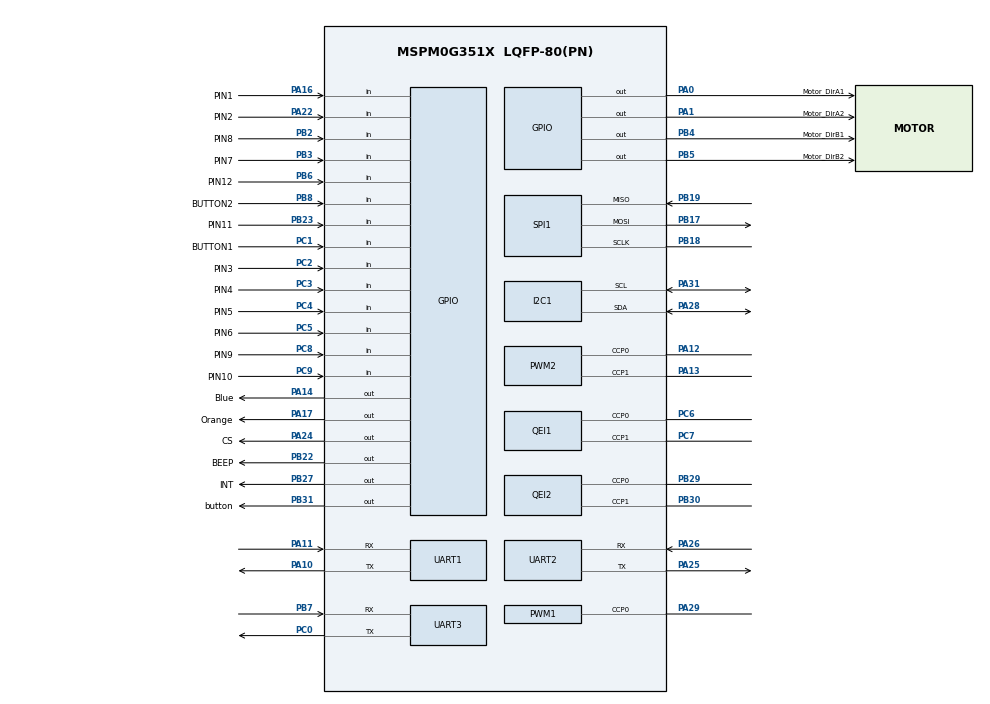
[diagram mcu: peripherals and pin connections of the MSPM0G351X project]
/**
 *
 * @cliArgs --device "MSPM0G351X" --part "Default" --package "LQFP-80(PN)" --product "mspm0_sdk@2.11.00.07"
 * @versions {"tool":"1.28.0+4712"}
 */

/**
 * Import the modules used in this configuration.
 */
const GPIO          = scripting.addModule("/ti/driverlib/GPIO", {}, false);
const GPIO1         = GPIO.addInstance();
const GPIO2         = GPIO.addInstance();
const GPIO3         = GPIO.addInstance();
const GPIO4         = GPIO.addInstance();
const GPIO5         = GPIO.addInstance();
const I2C           = scripting.addModule("/ti/driverlib/I2C", {}, false);
const I2C1          = I2C.addInstance();
const PWM           = scripting.addModule("/ti/driverlib/PWM", {}, false);
const PWM1          = PWM.addInstance();
const PWM2          = PWM.addInstance();
const QEI           = scripting.addModule("/ti/driverlib/QEI", {}, false);
const QEI1          = QEI.addInstance();
const QEI2          = QEI.addInstance();
const SPI           = scripting.addModule("/ti/driverlib/SPI", {}, false);
const SPI1          = SPI.addInstance();
const SYSCTL        = scripting.addModule("/ti/driverlib/SYSCTL");
const SYSTICK       = scripting.addModule("/ti/driverlib/SYSTICK");
const TIMER         = scripting.addModule("/ti/driverlib/TIMER", {}, false);
const TIMER1        = TIMER.addInstance();
const UART          = scripting.addModule("/ti/driverlib/UART", {}, false);
const UART1         = UART.addInstance();
const UART2         = UART.addInstance();
const UART3         = UART.addInstance();
const ProjectConfig = scripting.addModule("/ti/project_config/ProjectConfig");

/**
 * Write custom configuration values to the imported modules.
 */
const divider9       = system.clockTree["UDIV"];
divider9.divideValue = 2;

const mux4       = system.clockTree["EXHFMUX"];
mux4.inputSelect = "EXHFMUX_XTAL";

const mux8       = system.clockTree["HSCLKMUX"];
mux8.inputSelect = "HSCLKMUX_SYSPLL2X";

const mux10       = system.clockTree["MFPCLKMUX"];
mux10.inputSelect = "MFPCLKMUX_HFCLK";

const mux12       = system.clockTree["SYSPLLMUX"];
mux12.inputSelect = "zSYSPLLMUX_HFCLK";

const pinFunction4       = system.clockTree["HFXT"];
pinFunction4.enable      = true;
pinFunction4.inputFreq   = 40;
pinFunction4.HFXTStartup = 100;

GPIO1.$name                          = "LED_Board";
GPIO1.port                           = "PORTA";
GPIO1.associatedPins.create(2);
GPIO1.associatedPins[0].$name        = "Blue";
GPIO1.associatedPins[0].initialValue = "SET";
GPIO1.associatedPins[0].pin.$assign  = "PA14";
GPIO1.associatedPins[1].$name        = "Orange";
GPIO1.associatedPins[1].initialValue = "SET";
GPIO1.associatedPins[1].pin.$assign  = "PA17";

const Board = scripting.addModule("/ti/driverlib/Board", {}, false);

GPIO2.$name                         = "Button";
GPIO2.port                          = "PORTB";
GPIO2.associatedPins[0].$name       = "button";
GPIO2.associatedPins[0].pin.$assign = "PB31";

GPIO3.$name                          = "GraySensor";
GPIO3.associatedPins.create(12);
GPIO3.associatedPins[0].$name        = "PIN1";
GPIO3.associatedPins[0].direction    = "INPUT";
GPIO3.associatedPins[0].pin.$assign  = "PA16";
GPIO3.associatedPins[1].$name        = "PIN2";
GPIO3.associatedPins[1].direction    = "INPUT";
GPIO3.associatedPins[1].pin.$assign  = "PA22";
GPIO3.associatedPins[2].$name        = "PIN3";
GPIO3.associatedPins[2].direction    = "INPUT";
GPIO3.associatedPins[2].pin.$assign  = "PC2";
GPIO3.associatedPins[3].$name        = "PIN4";
GPIO3.associatedPins[3].direction    = "INPUT";
GPIO3.associatedPins[3].pin.$assign  = "PC3";
GPIO3.associatedPins[4].$name        = "PIN5";
GPIO3.associatedPins[4].direction    = "INPUT";
GPIO3.associatedPins[4].pin.$assign  = "PC4";
GPIO3.associatedPins[5].$name        = "PIN6";
GPIO3.associatedPins[5].direction    = "INPUT";
GPIO3.associatedPins[5].pin.$assign  = "PC5";
GPIO3.associatedPins[6].$name        = "PIN7";
GPIO3.associatedPins[6].direction    = "INPUT";
GPIO3.associatedPins[6].pin.$assign  = "PB3";
GPIO3.associatedPins[7].$name        = "PIN8";
GPIO3.associatedPins[7].direction    = "INPUT";
GPIO3.associatedPins[7].pin.$assign  = "PB2";
GPIO3.associatedPins[8].$name        = "PIN9";
GPIO3.associatedPins[8].direction    = "INPUT";
GPIO3.associatedPins[8].pin.$assign  = "PC8";
GPIO3.associatedPins[9].$name        = "PIN10";
GPIO3.associatedPins[9].direction    = "INPUT";
GPIO3.associatedPins[9].pin.$assign  = "PC9";
GPIO3.associatedPins[10].$name       = "PIN11";
GPIO3.associatedPins[10].direction   = "INPUT";
GPIO3.associatedPins[10].pin.$assign = "PB23";
GPIO3.associatedPins[11].$name       = "PIN12";
GPIO3.associatedPins[11].direction   = "INPUT";
GPIO3.associatedPins[11].pin.$assign = "PB6";

GPIO4.$name                          = "ICM";
GPIO4.associatedPins.create(2);
GPIO4.associatedPins[0].$name        = "CS";
GPIO4.associatedPins[0].pin.$assign  = "PA24";
GPIO4.associatedPins[1].$name        = "INT";
GPIO4.associatedPins[1].assignedPort = "PORTB";
GPIO4.associatedPins[1].pin.$assign  = "PB27";

GPIO5.$name                              = "MESS";
GPIO5.associatedPins.create(7);
GPIO5.associatedPins[0].$name            = "BUTTON1";
GPIO5.associatedPins[0].direction        = "INPUT";
GPIO5.associatedPins[0].internalResistor = "PULL_UP";
GPIO5.associatedPins[0].pin.$assign      = "PC1";
GPIO5.associatedPins[1].$name            = "BUTTON2";
GPIO5.associatedPins[1].direction        = "INPUT";
GPIO5.associatedPins[1].internalResistor = "PULL_UP";
GPIO5.associatedPins[1].inputFilter      = "3_CYCLES";
GPIO5.associatedPins[1].pin.$assign      = "PB8";
GPIO5.associatedPins[2].$name            = "BEEP";
GPIO5.associatedPins[2].pin.$assign      = "PB22";
GPIO5.associatedPins[3].$name            = "Motor_DirA1";
GPIO5.associatedPins[3].pin.$assign      = "PA0";
GPIO5.associatedPins[4].$name            = "Motor_DirA2";
GPIO5.associatedPins[4].pin.$assign      = "PA1";
GPIO5.associatedPins[5].$name            = "Motor_DirB1";
GPIO5.associatedPins[5].pin.$assign      = "PB4";
GPIO5.associatedPins[6].$name            = "Motor_DirB2";
GPIO5.associatedPins[6].pin.$assign      = "PB5";

I2C1.$name                     = "I2C_0";
I2C1.basicEnableController     = true;
I2C1.peripheral.sdaPin.$assign = "PA28";
I2C1.peripheral.sclPin.$assign = "PA31";
I2C1.sdaPinConfig.$name        = "ti_driverlib_gpio_GPIOPinGeneric10";
I2C1.sclPinConfig.$name        = "ti_driverlib_gpio_GPIOPinGeneric11";

PWM1.ccIndex                            = [0];
PWM1.$name                              = "LED_Color";
PWM1.timerCount                         = 100;
PWM1.interrupts                         = ["LOAD_EVENT"];
PWM1.timerStartTimer                    = true;
PWM1.PWM_CHANNEL_0.$name                = "ti_driverlib_pwm_PWMTimerCC0";
PWM1.PWM_CHANNEL_0.dutyCycle            = 50;
PWM1.ccp0PinConfig.direction            = scripting.forceWrite("OUTPUT");
PWM1.ccp0PinConfig.hideOutputInversion  = scripting.forceWrite(false);
PWM1.ccp0PinConfig.onlyInternalResistor = scripting.forceWrite(false);
PWM1.ccp0PinConfig.passedPeripheralType = scripting.forceWrite("Digital");
PWM1.ccp0PinConfig.$name                = "ti_driverlib_gpio_GPIOPinGeneric6";
PWM1.peripheral.$assign                 = "TIMG6";
PWM1.peripheral.ccp0Pin.$assign         = "PA29";

PWM2.$name                              = "PWM_Motor";
PWM2.timerCount                         = 1001;
PWM2.peripheral.ccp0Pin.$assign         = "PA12";
PWM2.peripheral.ccp1Pin.$assign         = "PA13";
PWM2.PWM_CHANNEL_0.$name                = "ti_driverlib_pwm_PWMTimerCC1";
PWM2.PWM_CHANNEL_1.$name                = "ti_driverlib_pwm_PWMTimerCC2";
PWM2.ccp0PinConfig.direction            = scripting.forceWrite("OUTPUT");
PWM2.ccp0PinConfig.hideOutputInversion  = scripting.forceWrite(false);
PWM2.ccp0PinConfig.onlyInternalResistor = scripting.forceWrite(false);
PWM2.ccp0PinConfig.passedPeripheralType = scripting.forceWrite("Digital");
PWM2.ccp0PinConfig.$name                = "ti_driverlib_gpio_GPIOPinGeneric14";
PWM2.ccp1PinConfig.direction            = scripting.forceWrite("OUTPUT");
PWM2.ccp1PinConfig.hideOutputInversion  = scripting.forceWrite(false);
PWM2.ccp1PinConfig.onlyInternalResistor = scripting.forceWrite(false);
PWM2.ccp1PinConfig.passedPeripheralType = scripting.forceWrite("Digital");
PWM2.ccp1PinConfig.$name                = "ti_driverlib_gpio_GPIOPinGeneric15";

QEI1.$name                              = "QEI_1";
QEI1.timerStartTimer                    = true;
QEI1.peripheral.ccp0Pin.$assign         = "PC6";
QEI1.peripheral.ccp1Pin.$assign         = "PC7";
QEI1.ccp0PinConfig.hideOutputInversion  = scripting.forceWrite(false);
QEI1.ccp0PinConfig.onlyInternalResistor = scripting.forceWrite(false);
QEI1.ccp0PinConfig.passedPeripheralType = scripting.forceWrite("Digital");
QEI1.ccp0PinConfig.$name                = "ti_driverlib_gpio_GPIOPinGeneric2";
QEI1.ccp1PinConfig.hideOutputInversion  = scripting.forceWrite(false);
QEI1.ccp1PinConfig.onlyInternalResistor = scripting.forceWrite(false);
QEI1.ccp1PinConfig.passedPeripheralType = scripting.forceWrite("Digital");
QEI1.ccp1PinConfig.$name                = "ti_driverlib_gpio_GPIOPinGeneric3";

QEI2.$name                              = "QEI_0";
QEI2.timerStartTimer                    = true;
QEI2.peripheral.ccp0Pin.$assign         = "PB29";
QEI2.peripheral.ccp1Pin.$assign         = "PB30";
QEI2.ccp0PinConfig.hideOutputInversion  = scripting.forceWrite(false);
QEI2.ccp0PinConfig.onlyInternalResistor = scripting.forceWrite(false);
QEI2.ccp0PinConfig.passedPeripheralType = scripting.forceWrite("Digital");
QEI2.ccp0PinConfig.$name                = "ti_driverlib_gpio_GPIOPinGeneric0";
QEI2.ccp1PinConfig.hideOutputInversion  = scripting.forceWrite(false);
QEI2.ccp1PinConfig.onlyInternalResistor = scripting.forceWrite(false);
QEI2.ccp1PinConfig.passedPeripheralType = scripting.forceWrite("Digital");
QEI2.ccp1PinConfig.$name                = "ti_driverlib_gpio_GPIOPinGeneric1";

SPI1.$name                      = "SPI_0";
SPI1.enableDMAEvent1            = false;
SPI1.enableDMAEvent2            = false;
SPI1.frameFormat                = "MOTO3";
SPI1.chipSelect                 = [];
SPI1.polarity                   = "1";
SPI1.phase                      = "1";
SPI1.targetBitRate              = 6000000;
SPI1.sclkPinConfig.$name        = "ti_driverlib_gpio_GPIOPinGeneric7";
SPI1.mosiPinConfig.$name        = "ti_driverlib_gpio_GPIOPinGeneric8";
SPI1.misoPinConfig.$name        = "ti_driverlib_gpio_GPIOPinGeneric9";
SPI1.peripheral.$assign         = "SPI0";
SPI1.peripheral.sclkPin.$assign = "PB18";
SPI1.peripheral.mosiPin.$assign = "PB17";
SPI1.peripheral.misoPin.$assign = "PB19";

SYSCTL.clockTreeEn           = true;
SYSCTL.validateClkStatus     = true;
SYSCTL.forceDefaultClkConfig = true;

SYSTICK.periodEnable    = true;
SYSTICK.systickEnable   = true;
SYSTICK.interruptEnable = true;
SYSTICK.period          = 80000;

TIMER1.timerStartTimer  = true;
TIMER1.timerMode        = "PERIODIC_UP";
TIMER1.timerClkPrescale = 256;
TIMER1.interrupts       = ["LOAD"];
TIMER1.timerPeriod      = "0.001";
TIMER1.$name            = "TIMER_1ms";

UART1.$name                            = "UART_Sys";
UART1.profile                          = "CONFIG_PROFILE_1";
UART1.peripheral.$assign               = "UART0";
UART1.peripheral.rxPin.$assign         = "PA11";
UART1.peripheral.txPin.$assign         = "PA10";
UART1.txPinConfig.direction            = scripting.forceWrite("OUTPUT");
UART1.txPinConfig.hideOutputInversion  = scripting.forceWrite(false);
UART1.txPinConfig.onlyInternalResistor = scripting.forceWrite(false);
UART1.txPinConfig.passedPeripheralType = scripting.forceWrite("Digital");
UART1.txPinConfig.$name                = "ti_driverlib_gpio_GPIOPinGeneric4";
UART1.rxPinConfig.hideOutputInversion  = scripting.forceWrite(false);
UART1.rxPinConfig.onlyInternalResistor = scripting.forceWrite(false);
UART1.rxPinConfig.passedPeripheralType = scripting.forceWrite("Digital");
UART1.rxPinConfig.$name                = "ti_driverlib_gpio_GPIOPinGeneric5";

UART2.$name                            = "UART_ESP";
UART2.peripheral.rxPin.$assign         = "PA26";
UART2.peripheral.txPin.$assign         = "PA25";
UART2.txPinConfig.direction            = scripting.forceWrite("OUTPUT");
UART2.txPinConfig.hideOutputInversion  = scripting.forceWrite(false);
UART2.txPinConfig.onlyInternalResistor = scripting.forceWrite(false);
UART2.txPinConfig.passedPeripheralType = scripting.forceWrite("Digital");
UART2.txPinConfig.$name                = "ti_driverlib_gpio_GPIOPinGeneric12";
UART2.rxPinConfig.hideOutputInversion  = scripting.forceWrite(false);
UART2.rxPinConfig.onlyInternalResistor = scripting.forceWrite(false);
UART2.rxPinConfig.passedPeripheralType = scripting.forceWrite("Digital");
UART2.rxPinConfig.$name                = "ti_driverlib_gpio_GPIOPinGeneric13";

UART3.$name                            = "UART_PRINT";
UART3.targetBaudRate                   = 115200;
UART3.peripheral.rxPin.$assign         = "PB7";
UART3.peripheral.txPin.$assign         = "PC0";
UART3.txPinConfig.direction            = scripting.forceWrite("OUTPUT");
UART3.txPinConfig.hideOutputInversion  = scripting.forceWrite(false);
UART3.txPinConfig.onlyInternalResistor = scripting.forceWrite(false);
UART3.txPinConfig.passedPeripheralType = scripting.forceWrite("Digital");
UART3.txPinConfig.$name                = "ti_driverlib_gpio_GPIOPinGeneric16";
UART3.rxPinConfig.hideOutputInversion  = scripting.forceWrite(false);
UART3.rxPinConfig.onlyInternalResistor = scripting.forceWrite(false);
UART3.rxPinConfig.passedPeripheralType = scripting.forceWrite("Digital");
UART3.rxPinConfig.$name                = "ti_driverlib_gpio_GPIOPinGeneric17";

ProjectConfig.genLibIQ        = true;
ProjectConfig.genLibIQVersion = "MATHACL";
ProjectConfig.genLibCMSIS     = true;

/**
 * Pinmux solution for unlocked pins/peripherals. This ensures that minor changes to the automatic solver in a future
 * version of the tool will not impact the pinmux you originally saw.  These lines can be completely deleted in order to
 * re-solve from scratch.
 */
pinFunction4.peripheral.$suggestSolution           = "SYSCTL";
pinFunction4.peripheral.hfxInPin.$suggestSolution  = "PA5";
pinFunction4.peripheral.hfxOutPin.$suggestSolution = "PA6";
Board.peripheral.$suggestSolution                  = "DEBUGSS";
Board.peripheral.swclkPin.$suggestSolution         = "PA20";
Board.peripheral.swdioPin.$suggestSolution         = "PA19";
I2C1.peripheral.$suggestSolution                   = "I2C0";
PWM2.peripheral.$suggestSolution                   = "TIMG0";
QEI1.peripheral.$suggestSolution                   = "TIMG8";
QEI2.peripheral.$suggestSolution                   = "TIMG9";
TIMER1.peripheral.$suggestSolution                 = "TIMA0";
UART2.peripheral.$suggestSolution                  = "UART3";
UART3.peripheral.$suggestSolution                  = "UART1";
